# SF32LB57x register map
File version: 1.0
CPU: CM33 r0p1, little endian, MPU, FPU, 3 interrupt priority bits
Registers are 32-bit, read-write, reset 0x0 unless marked. A register's access mark holds for its fields unless they carry their own. Offsets are from the block's base; [hi:lo] are bit positions; {n}, {i} and the like mark numbered series; 'fields as' and 'values as' point back to an identical list.

## GPDMA
Base 0x50081000
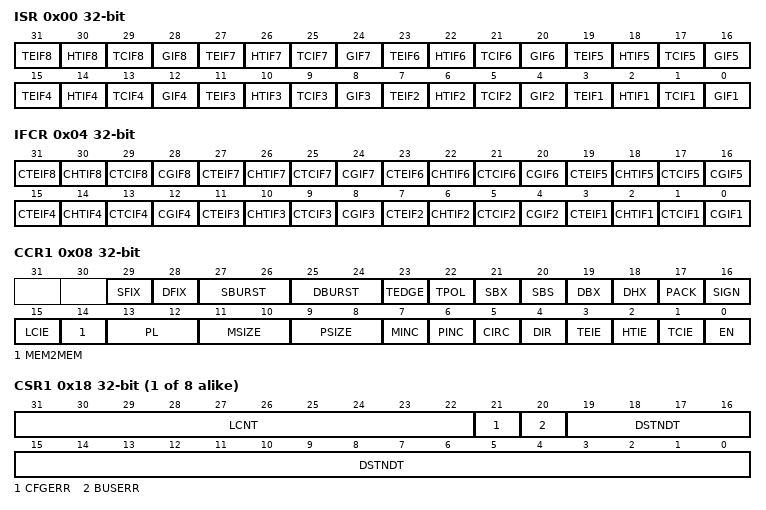
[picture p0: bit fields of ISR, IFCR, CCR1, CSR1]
0x00 ISR
  [4n-1] TEIF{n} (n=2..8) — channel transfer error flag
  [4n-2] HTIF{n} (n=2..8) — channel half transfer flag
  [4n-3] TCIF{n} (n=2..8) — channel transfer complete flag
  [4n-4] GIF{n} (n=2..8) — channel global interrupt flag
  [3] TEIF1 — channel transfer error flag. Set when bus error detected. Cleared when write 1 to CTEIF or CGIF.
  [2] HTIF1 — channel half transfer flag. Set when half NDT are transferred. Cleared when write 1 to CHTIF or CGIF.
  [1] TCIF1 — channel transfer complete flag. Set when all NDT are transferred. Cleared when write 1 to CTCIF or CGIF.
  [0] GIF1 — channel global interrupt flag. Set when any of TEIF/HTIF/TCIF asserted. Cleared when TEIF/HTIF/TCIF all cleared.
0x04 IFCR
  [4n-1] CTEIF{n} (n=2..8) — CTEIF, transfer error flag clear
  [4n-2] CHTIF{n} (n=2..8) — CHTIF, half transfer flag clear
  [4n-3] CTCIF{n} (n=2..8) — CTCIF, transfer complete flag clear
  [4n-4] CGIF{n} (n=2..8) — CGIF, global interrupt flag clear
  [3] CTEIF1 — CTEIF, transfer error flag clear. Write 1 to clear TEIF.
  [2] CHTIF1 — CHTIF, half transfer flag clear. Write 1 to clear HTIF.
  [1] CTCIF1 — CTCIF, transfer complete flag clear. Write 1 to clear TCIF.
  [0] CGIF1 — CGIF, global interrupt flag clear. Write 1 to clear all TEIF/HTIF/TCIF.
0x08 CCR1
  [29] SFIX — source burst initial address fix mode 0: burst address will increase normally 1: initial address of each source burst is fixed, but sequential address during source burst will increase normally
  [28] DFIX — destination burst start address fix mode 0: burst address will increase normally 1: initial address of each destination burst is fixed, but sequential address during destination burst will increase normally
  [27:26] SBURST — source max burst beats if possible. Should set to 0 if source increment mode is 0. 00: SINGLE, single burst. 01: INCR4, 4-beat incrementing burst 10: INCR8, 8-beat incrementing burst 11: INCR16, 16-beat incrementing burst
  [25:24] DBURST — destination max burst beats if possible. Should set to 0 if destination increment mode is 0. 00: SINGLE, single burst. 01: INCR4, 4-beat incrementing burst 10: INCR8, 8-beat incrementing burst 11: INCR16, 16-beat incrementing burst
  [23] TEDGE — channel trigger mode 0: level mode 1: edge mode
  [22] TPOL — channel trigger polarity 0: high level or positive edge 1: low level or negtive edge
  [21] SBX — source byte exchange within the unaligned half-word of each source word 0: no byte-based exchange within the unaligned half-word of each source word 1: the two consecutive bytes within the unaligned half-word of each source word are exchanged.
  [20] SBS — source cyclic byte-right-shift within each source word 0: no shift 1: each byte is cyclic right-shifted within each source word, thus the least byte becomes the highest byte.
  [19] DBX — destination byte exchange 0: no byte-based exchange within half-word 1: the two consecutive bytes are exchanged in each destination half-word.
  [18] DHX — destination half-word exchange 0: no halfword-based exchanged within word 1: the two consecutive half-words are exchanged in each destination word.
  [17] PACK — pack/unpack mode when source size and destination size are different 0: no pack/unpack 1: pack/unpack
  [16] SIGN — sign extention mode when source size and destination size are different and no pack/unpack 0: zero bit extention 1: sign bit extention
  [15] LCIE — list complete interrupt enable 0: disabled 1: enabled
  [14] MEM2MEM — memory-to-memory mode 0: disabled 1: enabled
  [13:12] PL — priority level 00: low 01: medium 10: high 11: very high
  [11:10] MSIZE — memory size Defines the data size of each DMA transfer to the identified memory. In memory-to-memory mode, this field identifies the memory source if DIR = 1 and the memory destination if DIR = 0. In peripheral-to-peripheral mode, this field identifies the peripheral source if DIR = 1 and the peripheral destination if DIR = 0. 00: 8 bits 01: 16 bits 10: 32 bits 11: 24 bits
  [9:8] PSIZE — peripheral size Defines the data size of each DMA transfer to the identified peripheral. In memory-to-memory mode, this field identifies the memory destination if DIR = 1 and the memory source if DIR = 0. In peripheral-to-peripheral mode, this field identifies the peripheral destination if DIR = 1 and the peripheral source if DIR = 0. 00: 8 bits 01: 16 bits 10: 32 bits 11: 24 bits
  [7] MINC — memory increment mode Defines the increment mode for each DMA transfer to the identified memory. In memory-to-memory mode, this field identifies the memory source if DIR = 1 and the memory destination if DIR = 0. In peripheral-to-peripheral mode, this field identifies the peripheral source if DIR = 1 and the peripheral destination if DIR = 0. 0: disabled 1: enabled
  [6] PINC — peripheral increment mode Defines the increment mode for each DMA transfer to the identified peripheral. n memory-to-memory mode, this field identifies the memory destination if DIR = 1 and the memory source if DIR = 0. In peripheral-to-peripheral mode, this field identifies the peripheral destination if DIR = 1 and the peripheral source if DIR = 0. 0: disabled 1: enabled
  [5] CIRC — circular mode 0: disabled 1: enabled
  [4] DIR — data transfer direction This bit must be set only in memory-to-peripheral and peripheral-to-memory modes. 0: read from peripheral – Source attributes are defined by PSIZE and PINC, plus the CPARx register. This is still valid in a memory-to-memory mode. – Destination attributes are defined by MSIZE and MINC, plus the CM0/1ARx register. This is still valid in a peripheral-to-peripheral mode. 1: read from memory – Destination attributes are defined by PSIZE and PINC, plus the CPARx register. This is still valid in a memory-to-memory mode. – Source attributes are defined by MSIZE and MINC, plus the CM0/1ARx register. This is still valid in a peripheral-to-peripheral mode.
  [3] TEIE — transfer error interrupt enable 0: disabled 1: enabled
  [2] HTIE — half transfer interrupt enable 0: disabled 1: enabled
  [1] TCIE — transfer complete interrupt enable 0: disabled 1: enabled
  [0] EN — channel enable When a channel transfer error occurs, this bit is cleared by hardware. It can not be set again by software (channel x re-activated) until the TEIFx bit of the ISR register is cleared (by setting the CTEIFx bit of the IFCR register). 0: disabled 1: enabled
0x0C CNDTR1
  [19:0] NDT — number of data to transfer (0 to 2^20 - 1) This field is updated by hardware when the channel is enabled: – It is decremented after each single DMA ‘read’ transfer, indicating the remaining amount of data items to read. – It is kept at zero when the programmed amount of data to transfer is reached, if the channel is not in circular mode (CIRC = 0 in the CCRx register). – It is reloaded automatically by the previously programmed value, when the transfer is complete, if the channel is in circular mode (CIRC = 1). Transfer is completed when both NDT and DSTNDT reach zero. If this field is zero, no transfer can be served whatever the channel status (enabled or not).
0x10 CPAR1
  [31:0] PA — peripheral address It contains the base address of the peripheral data register from/to which the data will be read/written. When PSIZE[1:0] = 01 (16 bits), should align to a half-word address. When PSIZE[1] = 1 (32/24 bits), should align to a word address. In memory-to-memory mode, this register identifies the memory destination address if DIR = 1 and the memory source address if DIR = 0. In peripheral-to-peripheral mode, this register identifies the peripheral destination address DIR = 1 and the peripheral source address if DIR = 0.
{0x0+0x14*i} CM0AR{i} (i=1..8)
  [31:0] MA — memory address It contains the base address of the memory from/to which the data will be read/written. When MSIZE[1:0] = 01 (16 bits), should align to a half-word address. When MSIZE[1] = 1 (32/24 bits), should align to a word address. In memory-to-memory mode, this register identifies the memory source address if DIR = 1 and the memory destination address if DIR = 0. In peripheral-to-peripheral mode, this register identifies the peripheral source address DIR = 1 and the peripheral destination address if DIR = 0.
{0x4+0x14*i} CSR{i} (i=1..8)
  [31:22] LCNT — counter of completed lists. Cleared when linked-list starts. After each list transfer completes (both NDT and DSTNDT come to 0), LCNT is increased by 1, no matter whether next list have been triggered.
  [21] CFGERR — indicate configuration error occurs
  [20] BUSERR — indicate bus error occurs
  [19:0] DSTNDT — indicate number of destination data to transfer (0 to 2^20 - 1) This field is updated by hardware when the channel is enabled, and should not be programmed by software – It is decremented after each single DMA ‘write’ transfer, indicating the remaining amount of data items to transfer. – It is reloaded automatically, when the transfer is complete, if the channel is in circular mode (CIRC = 1).
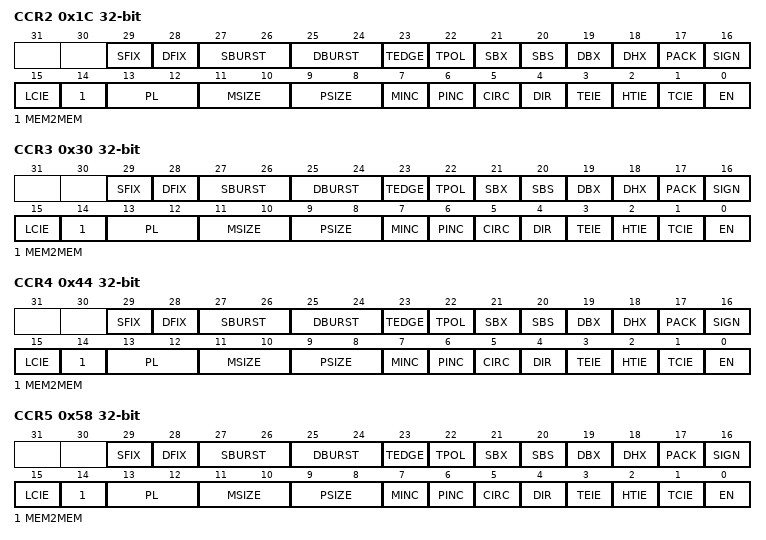
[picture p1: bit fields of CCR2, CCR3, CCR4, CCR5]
0x1C CCR2
  fields as CCR1
0x20 CNDTR2
  fields as CNDTR1
0x24 CPAR2
  fields as CPAR1
0x30 CCR3
  fields as CCR1
0x34 CNDTR3
  fields as CNDTR1
0x38 CPAR3
  fields as CPAR1
0x44 CCR4
  fields as CCR1
0x48 CNDTR4
  fields as CNDTR1
0x4C CPAR4
  fields as CPAR1
0x58 CCR5
  fields as CCR1
0x5C CNDTR5
  fields as CNDTR1
0x60 CPAR5
  fields as CPAR1
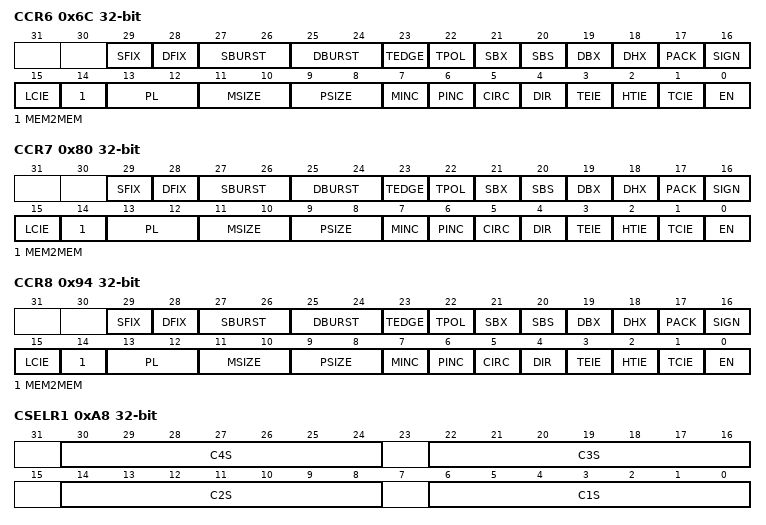
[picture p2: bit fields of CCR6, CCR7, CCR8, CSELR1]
0x6C CCR6
  fields as CCR1
0x70 CNDTR6
  fields as CNDTR1
0x74 CPAR6
  fields as CPAR1
0x80 CCR7
  fields as CCR1
0x84 CNDTR7
  fields as CNDTR1
0x88 CPAR7
  fields as CPAR1
0x94 CCR8
  fields as CCR1
0x98 CNDTR8
  fields as CNDTR1
0x9C CPAR8
  fields as CPAR1
0xA8 CSELR1
  [8n-2:8n-8] C{n}S (n=1..4) — DMA channel {n} request selection
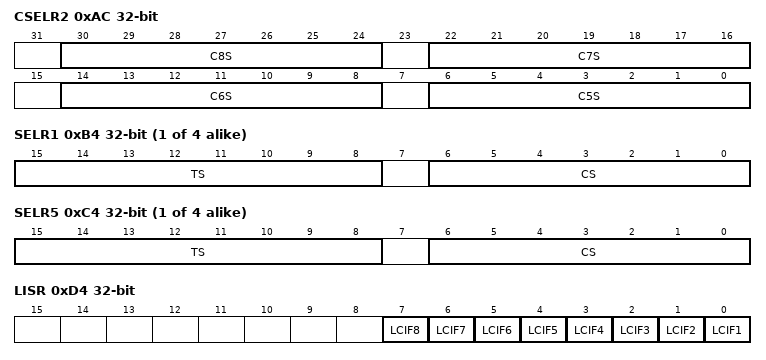
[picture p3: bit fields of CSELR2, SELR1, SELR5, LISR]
0xAC CSELR2
  [8n-34:8n-40] C{n}S (n=5..8) — DMA channel {n} request selection
0xB0 DBGSEL
  [3:0] DBGSEL — Debug data selection
{0xB0+4i} SELR{i} (i=1..4)
  [15:8] TS — DMA channel {i} trigger selection
  [6:0] CS — DMA channel {i} request selection. It's a mirror register of CSELR1.C{i}S
{0xB0+4i} SELR{i} (i=5..8)
  [15:8] TS — DMA channel {i} trigger selection
  [6:0] CS — DMA channel {i} request selection. It's a mirror register of CSELR2.C{i}S
0xD4 LISR
  [n-1] LCIF{n} (n=1..8) — channel {n} list/repetition complete flag
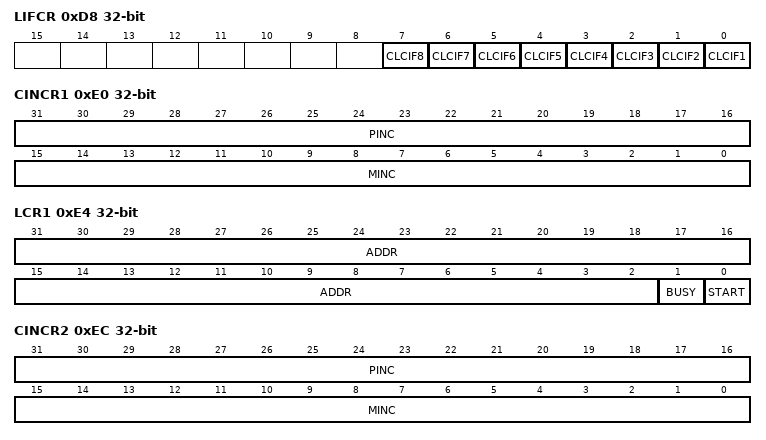
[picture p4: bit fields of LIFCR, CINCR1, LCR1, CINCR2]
0xD8 LIFCR
  [n-1] CLCIF{n} (n=1..8) — channel {n} list/repetition complete flag clear
0xDC CREPR1
  [9:0] CNT — repeat counter 0,1: no repetition others: repetition mode. Dma transfer will repeat for CNT times in direct mode. PA and MA may increase after each repetition.
0xE0 CINCR1
  [31:16] PINC — peripheral address increment PA will be increased by PINC each time dma transfer done in repetition mode
  [15:0] MINC — memory address increment MA will be increased by MINC each time dma transfer done in repetition mode
0xE4 LCR1
  [31:2] ADDR — linked-list address bit 31 to 2. address bit 1 and bit 0 is fixed to 0 (word aligned). Write before linked-list start as list start address. Read value indicate bit 31 to 2 of current list address if list has not been triggered, or next list address if current list has been triggered. After all lists finished, read value will be bit 31 to 2 of (last list address + 16)
  [1] BUSY — linked-list busy 0: linked-list transfer idle 1: linked-list transfer is busy
  [0] START — write 1 to start linked-list transfer. Will be cleared automatically
0xE8 CREPR2
  fields as CREPR1
0xEC CINCR2
  fields as CINCR1
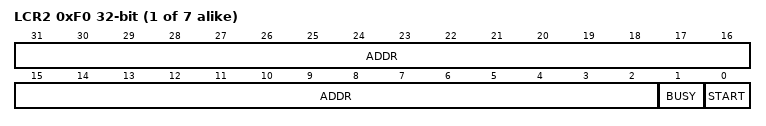
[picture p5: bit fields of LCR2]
{0xE8+4i} LCR{i} (i=2..8)
  fields as LCR1
